# AM335x register map
Vendor: Texas Instruments; Series: Sitara AM335x; File version: 1.1
CPU: Cortex-A8 r0p0, little endian
Registers are 32-bit, read-write, reset 0x0 unless marked. A register's access mark holds for its fields unless they carry their own. Offsets are from the block's base; [hi:lo] are bit positions.

## UART — UART0 module
Base 0x44E09000
0x00 THR
  [7:0] THR wo — Transmit holding register.[Value 0 to FFh.]
0x00 RHR
  [7:0] RHR ro — Receive holding register..[Value 0 to FFh.]
0x00 DLL
  [7:0] CLOCK_LSB — Divisor latches low.Stores the 8 LSB divisor value.[Value 0 to FFh.]
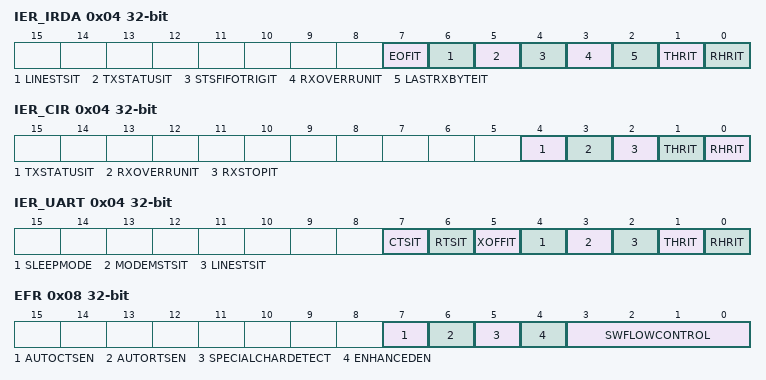
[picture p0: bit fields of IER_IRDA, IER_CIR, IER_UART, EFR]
0x04 IER_IRDA
  [7] EOFIT — bit: 7 (RW) received EOF interrupt [0x0 = disable; 0x1 = enable ]
  [6] LINESTSIT — bit: 6 (RW) receiver line status interrupt [0x0 = disable; 0x1 = enable ]
  [5] TXSTATUSIT — bit: 5 (RW) TX status interrupt [0x0 = disable; 0x1 = enable ]
  [4] STSFIFOTRIGIT — bit: 4 (RW) status FIFO trigger level interrupt [0x0 = disable; 0x1 = enable ]
  [3] RXOVERRUNIT — bit: 3 (RW) RX overrun interrupt [0x0 = disable; 0x1 = enable ]
  [2] LASTRXBYTEIT — bit: 2 (RW) last byte of frame in RX FIFO interrupt [0x0 = disable; 0x1 = enable ]
  [1] THRIT — bit: 1 (RW) THR interrupt [0x0 = disable; 0x1 = enable ]
  [0] RHRIT — bit: 0 (RW) RHR interrupt [0x0 = disable; 0x1 = enable ]
0x04 IER_CIR
  [4] TXSTATUSIT — bit: 5 (RW) TX status interrupt [0x0 = disable; 0x1 = enable ]
  [3] RXOVERRUNIT — bit: 3 (RW) RX overrun interrupt [0x0 = disable; 0x1 = enable ]
  [2] RXSTOPIT — bit: 2 (RW) RX stop interrupt [0x0 = disable; 0x1 = enable ]
  [1] THRIT — bit: 1 (RW) THR interrupt [0x0 = disable; 0x1 = enable ]
  [0] RHRIT — bit: 0 (RW) RHR interrupt [0x0 = disable; 0x1 = enable ]
0x04 IER_UART
  [7] CTSIT — bit: 7 (RW) Can be written only when EFR.ENHANCEDEN = 1. CTS (active-low) interrupt [0x0 = disable; 0x1 = enable ]
  [6] RTSIT — bit: 6 (RW) Can be written only when EFR.ENHANCEDEN = 1. RTS (active-low) interrupt [0x0 = disable; 0x1 = enable ]
  [5] XOFFIT — bit: 5 (RW) Can be written only when EFR.ENHANCEDEN = 1. XOFF interrupt [0x0 = disable; 0x1 = enable ]
  [4] SLEEPMODE — bit: 4 (RW) Can be only written when EFR.ENHANCEDEN = 1. Sleep mode
  [3] MODEMSTSIT — bit: 3 (RW) modem status register interrupt [0x0 = disable; 0x1 = enable ]
  [2] LINESTSIT — bit: 2 (RW) receiver line status interrupt [0x0 = disable; 0x1 = enable ]
  [1] THRIT — bit: 1 (RW) THR interrupt [0x0 = disable; 0x1 = enable ]
  [0] RHRIT — bit: 0 (RW) RHR interrupt and time out interrupt [0x0 = disable; 0x1 = enable ]
0x04 DLH
  [5:0] CLOCK_MSB — Divisor latches high. Stores the 6 MSB divisor value.[Value 0x0 to 0x3F.]
0x08 EFR
  [7] AUTOCTSEN — bit: 7 (RW) Auto-CTS enable bit (UART mode only). [0x0 = Normal operation.; 0x1 = Auto-CTS flow control is enabled; transmission is halted when
  [6] AUTORTSEN — bit: 6 (RW) Auto-RTS enable bit (UART mode only). [0x0 = Normal operation.; 0x1 = Auto-RTS flow control is enabled; RTS (active-low) pin goes
  [5] SPECIALCHARDETECT — bit: 5 (RW) Special character detect (UART mode only).[0x0 = Normal operation.; 0x1 = Special character
  [4] ENHANCEDEN — bit: 4 (RW) Enhanced functions write enable bit.Writing to IER[7:4], FCR[5:4], and MCR[7:5].[see e_ENH]
  [3:0] SWFLOWCONTROL — Combinations of software flow control can be selected by programming this bit. [ see e_SW_TX_FLOW_CTRL and e_SW_RX_FLOW_CTRL]
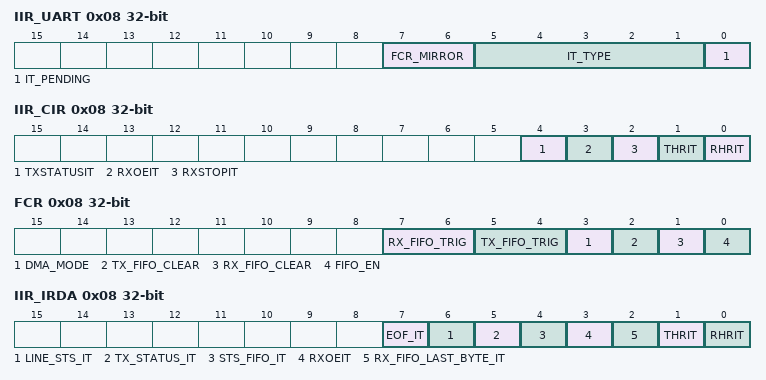
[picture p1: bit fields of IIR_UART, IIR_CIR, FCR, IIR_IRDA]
0x08 IIR_UART
  [7:6] FCR_MIRROR — Mirror the contents of FCR[0] on both bits.
  [5:1] IT_TYPE — Seven possible interrupts in UART mode. Other combinations never occur: [see e_IT_TYPES]
  [0] IT_PENDING — bit: 0 (RW) Interrupt pending. [0x0 = An interrupt is pending.; 0x1 = No interrupt is pending.]
0x08 IIR_CIR
  [4] TXSTATUSIT — bit: 5 (RW) TX status interrupt [0x0 = inactive; 0x1 = active ]
  [3] RXOEIT — bit: 3 (RW) RX overrun interrupt [0x0 = inactive; 0x1 = active ]
  [2] RXSTOPIT — bit: 2 (RW) Receive stop interrupt [0x0 = inactive; 0x1 = active ]
  [1] THRIT — bit: 1 (RW) THR interrupt [0x0 = inactive; 0x1 = active ]
  [0] RHRIT — bit: 0 (RW) RHR interrupt [0x0 = inactive; 0x1 = active ]
0x08 FCR
  [7:6] RX_FIFO_TRIG — bit: 6,7 (RW) Sets the trigger level for the RX FIFO: If SCR[7] = 0 and TLR[7] to
  [5:4] TX_FIFO_TRIG — bit: 4,5 (W) Can be written only if EFR.ENHANCEDEN = 1. Sets the trigger level for the TX FIFO: If SCR[6] = 0 and TLR[3] to
  [3] DMA_MODE — bit: 3 (W) Can be changed only when the baud clock is not running (DLL and DLH cleared to 0).
  [2] TX_FIFO_CLEAR — bit: 2 (W) [ 0x0 = No change.;
  [1] RX_FIFO_CLEAR — bit: 1 (W) [ 0x0 = No change.;
  [0] FIFO_EN — bit: 0 (W) Can be changed only when the baud clock is not running (DLL and DLH cleared to 0). [0x0 = Disables rcv FIFO; 0x1 = Enables rcv FIFO ]
0x08 IIR_IRDA
  [7] EOF_IT — bit: 7 (R) Received EOF [0x0 = inactive; 0x1 = active ]
  [6] LINE_STS_IT — bit: 6 (R) Receiver line status interrupt [0x0 = inactive; 0x1 = active ]
  [5] TX_STATUS_IT — bit: 5 (R) TX status interrupt [0x0 = inactive; 0x1 = active ]
  [4] STS_FIFO_IT — bit: 4 (R) Status FIFO trigger level interrupt [0x0 = inactive; 0x1 = active ]
  [3] RXOEIT — bit: 3 (R) RX overrun interrupt [0x0 = inactive; 0x1 = active ]
  [2] RX_FIFO_LAST_BYTE_IT — bit: 2 (R) Last byte of frame in RX FIFO interrupt [0x0 = inactive; 0x1 = active ]
  [1] THRIT — bit: 1 (R) THR interrupt [0x0 = inactive; 0x1 = active ]
  [0] RHRIT — bit: 0 (R) RHR interrupt [0x0 = inactive; 0x1 = active ]
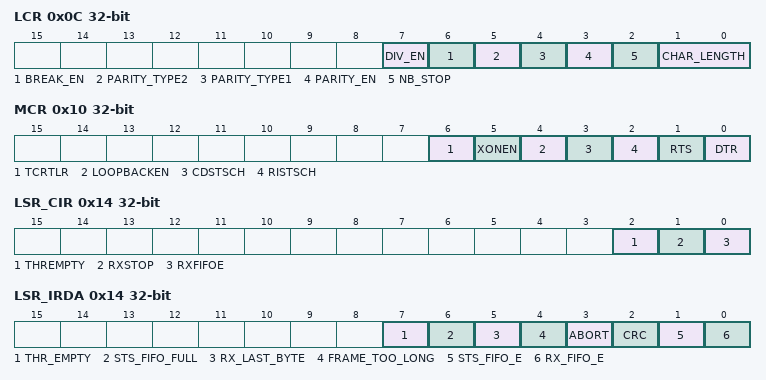
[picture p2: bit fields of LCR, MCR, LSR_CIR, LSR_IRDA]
0x0C LCR
  [7] DIV_EN — bit: 7 (RW) Divisor latch enable. [0x0 = Normal operating condition.;
  [6] BREAK_EN — bit: 6 (RW) Break control bit. Note: When LCR[6] is set to 1, the TX line is forced to 0 and remains
  [5] PARITY_TYPE2 — bit: 5 (RW) If LCR[3] = 1, then: [0x0 = If LCR[5] = 0, LCR[4] selects the forced parity format.;
  [4] PARITY_TYPE1 — bit: 4 (RW) If LCR[3] = 1, then: [0x0 = Odd parity is generated.; 0x1 = Even parity is generated. ]
  [3] PARITY_EN — bit: 3 (RW) Parity bit. [0x0 = No parity;
  [2] NB_STOP — bit: 2 (RW) Specifies the number of stop bits. [0x0 = 1 stop bit (word length = 5, 6, 7, 8).;
  [1:0] CHAR_LENGTH — bit: 0,1 (RW) Specifies the word length to be transmitted or received. [ see e_CHAR_LENGHT ]
0x10 MCR
  [6] TCRTLR — bit: 6 (RW) Can be written only when EFR.ENHANCEDEN = 1. [0x0 = No action.; 0x1 = Enables access to the TCR and TLR registers. ]
  [5] XONEN — bit: 5 (RW) Can be written only when EFR.ENHANCEDEN = 1. [0x0 = Disable XON any function.; 0x1 = Enable XON any function. ]
  [4] LOOPBACKEN — bit: 4 (RW) Loopback mode enable. [0x0 = Normal operating mode.; 0x1 = Enable local loopback mode (internal). In this mode, the
  [3] CDSTSCH — bit: 3 (RW) CDSTSCH. [0x0 = In loopback mode, forces DCD (active-low) input high and IRQ outputs to INACTIVE state.;
  [2] RISTSCH — bit: 2 (RW) RISTSCH. [ 0x0 = In loopback mode, forces RI (active-low) input inactive (high).;
  [1] RTS — bit: 1 (RW) In loopback mode, controls MSR[4]. If auto-RTS is enabled, the RTS (active-low) output is controlled by
  [0] DTR — bit: 0 (RW) DTR. [0x0 = Force DTR (active-low) output (used in loopback mode) to inactive (high).;
0x10 XON1_ADDR1
  [7:0] XONWORD1 — Stores the 8 bit XON1 character in UART modes and ADDR1 address 1 in IrDA modes.
0x14 XON2_ADDR2
  [7:0] XONWORD2 — Stores the 8 bit XON2 character in UART modes and ADDR2 address 2 in IrDA modes.
0x14 LSR_CIR
  [2] THREMPTY — bit: 4 (R) THREMPTY. [ 0x0 = Transmit holding register (TX FIFO) is not empty.;
  [1] RXSTOP — bit: 2 (R) The RXSTOP is generated based on the value set in the BOF
  [0] RXFIFOE — bit: 0 (R) RXFIFOE. [0x0 = At least one data character in the RX FIFO.;
0x14 LSR_IRDA
  [7] THR_EMPTY — bit: 7 (R) [0x0 = Transmit holding register (TX FIFO) is not empty;
  [6] STS_FIFO_FULL — bit: 6 (R) [0x0 = Status FIFO is not full.; 0x1 = Status FIFO is full. ]
  [5] RX_LAST_BYTE — bit: 5 (R) [0x0 = The RX FIFO (RHR) does not contain the last byte of the frame to be read.;
  [4] FRAME_TOO_LONG — bit: 4 (R) [0x0 = No frame-too-long error in frame.; 0x1 = Frame-too-long error in the frame at the top of the status FIFO
  [3] ABORT — bit: 3 (R) [0x0 = No abort pattern error in frame.; 0x1 = Abort pattern received. SIR and MIabort pattern. FIR: Illegal symbol. ]
  [2] CRC — bit: 2 (R) [0x0 = No CRC error in frame.; 0x1 = CRC error in the frame at the top of the status FIFO (next character to be read). ]
  [1] STS_FIFO_E — bit: 1 (R) [0x0 = Status FIFO is not empty.; 0x1 = Status FIFO is empty. ]
  [0] RX_FIFO_E — bit: 0 (R) [0x0 = At least one data character in the RX FIFO.; 0x1 = No data in the receive FIFO. ]
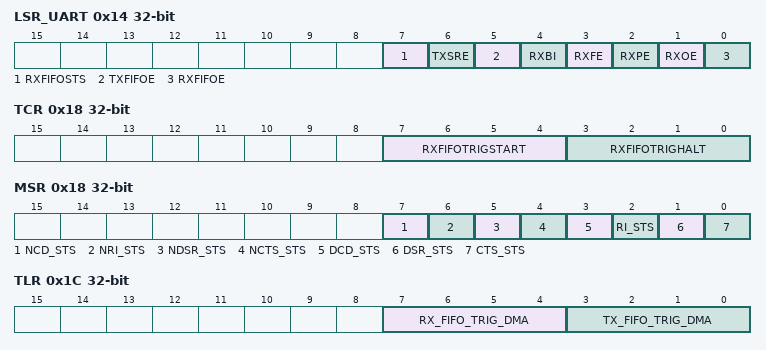
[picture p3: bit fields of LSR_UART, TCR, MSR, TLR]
0x14 LSR_UART
  [7] RXFIFOSTS — bit: 7 (R) [0x0 = Normal operation.;
  [6] TXSRE — bit: 6 (R) [0x0 = Transmitter hold (TX FIFO) and shift registers are not empty.;
  [5] TXFIFOE — bit: 5 (R) [0x0 = Transmit hold register (TX FIFO) is not empty.;
  [4] RXBI — bit: 4 (R) [0x0 = No break condition.; 0x1 = A break was detected while the data being read from the RX
  [3] RXFE — bit: 3 (R) [0x0 = No framing error in data being read from RX FIFO.;
  [2] RXPE — bit: 2 (R) [0x0 = No parity error in data being read from RX FIFO.; 0x1 = Parity error in data being read from RX FIFO. ]
  [1] RXOE — bit: 1 (R) [0x0 = No overrun error.; 0x1 = Overrun error occurred. Set when the character held in the
  [0] RXFIFOE — bit: 0 (R) [0x0 = No data in the receive FIFO.; 0x1 = At least one data character in the RX FIFO. ]
0x18 TCR
  [7:4] RXFIFOTRIGSTART — RX FIFO trigger level to RESTORE transmission (0 to 60).
  [3:0] RXFIFOTRIGHALT — RX FIFO trigger level to HALT transmission (0 to 60).
0x18 MSR
  [7] NCD_STS — bit: 7 (R) This bit is the complement of the DCD (active-low) input.
  [6] NRI_STS — bit: 6 (R) This bit is the complement of the RI (active-low) input.
  [5] NDSR_STS — bit: 5 (R) This bit is the complement of the DSR (active-low) input.
  [4] NCTS_STS — bit: 4 (R) This bit is the complement of the CTS (active-low) input.
  [3] DCD_STS — bit: 3 (R) DCD_STS.[0x0 = No change.; 0x1 = Indicates that DCD (active-low) input (or MCR[3] in loopback
  [2] RI_STS — bit: 2 (R) RI_STS. [0x0 = No change.; 0x1 = Indicates that RI (active-low) input (or MCR[2] in loopback
  [1] DSR_STS — bit: 1 (R) DSR_STS.[0x0 = No change.; 0x1 = Indicates that DSR (active-low) input (or MCR[0] in loopback
  [0] CTS_STS — bit: 0 (R) CTS_STS.[0x0 = No change.; 0x1 = Indicates that CTS (active-low) input (or MCR[1] in loopback
0x18 XOFF1
  [7:0] XOFFWORD1 — Stores the 8 bit XOFF1 character in UART modes.
0x1C SPR
  [7:0] SPR_WORD — Scratchpad register.
0x1C TLR
  [7:4] RX_FIFO_TRIG_DMA — Receive FIFO trigger level.
  [3:0] TX_FIFO_TRIG_DMA — Transmit FIFO trigger level.
0x1C XOFF2
  [7:0] XOFFWORD2 — Stores the 8 bit XOFF2 character in UART modes.
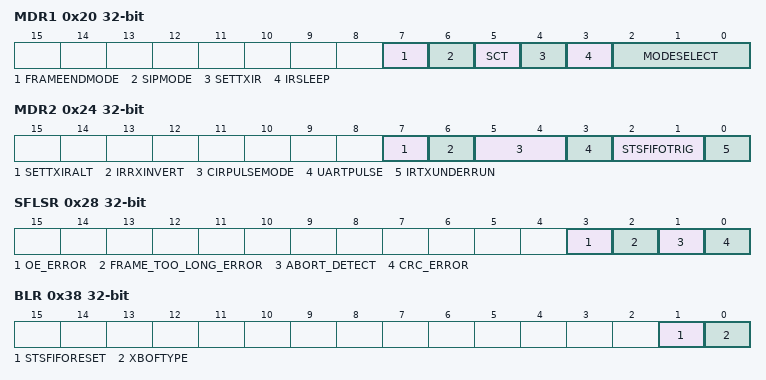
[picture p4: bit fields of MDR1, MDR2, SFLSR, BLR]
0x20 MDR1
  [7] FRAMEENDMODE — bit: 7 (RW) IrDA mode only. [0x0 = Frame-length method.; 0x1 = Set EOT bit method. ]
  [6] SIPMODE — bit: 6 (RW) MIR/FIR modes only. [0x0 = Manual SIP mode: SIP is generated with the control of ACREG[3].;
  [5] SCT — bit: 5 (RW) Store and control the transmission. [0x0 = Starts the infrared transmission when a value is written to the THR register.;
  [4] SETTXIR — bit: 4 (RW) Used to configure the infrared transceiver. [0x0 = If MDR2[7] = 0, no action; if MDR2[7] = 1, TXIR pin output is forced low.;
  [3] IRSLEEP — bit: 3 (RW) IrDA/CIR sleep mode. [0x0 = disabled; 0x1 = enabled ]
  [2:0] MODESELECT — UART/IrDA/CIR mode selection. [ see e_MODESELECT ]
0x24 MDR2
  [7] SETTXIRALT — bit: 7 (RW) Provides alternate functionality for MDR1[4]. [0x0 = Normal mode; 0x1 = Alternate mode for SETTXIR ]
  [6] IRRXINVERT — bit: 6 (RW) Only for IR mode (IrDA and CIR).
  [5:4] CIRPULSEMODE — bit: 4,5 (RW) CIR pulse modulation definition. Defines high level of the pulse width associated with a digit:[ see e_CIRPULSE_MODULATION ]
  [3] UARTPULSE — bit: 3 (RW) UART mode only.Used to allow pulse shaping in UART mode.[0x0 = Normal UART mode.; 0x1 = UART mode with pulse shaping. ]
  [2:1] STSFIFOTRIG — bit: 1,2 (RW) Only for IrDA mode.Frame status FIFO threshold select: [see e_IRDA_FIFO_TIRGLVL ]
  [0] IRTXUNDERRUN — bit: 0 (R) IrDA transmission status interrupt. [0x0 = frame was transmitted successfully without error.;
0x28 TXFLL
  [7:0] TXFLL wo — LSB register used to specify the frame length.
0x28 SFLSR
  [3] OE_ERROR — bit: 4 (R) [0x0 = No error; 0x1 = Overrun error in RX FIFO when frame at top of RX FIFO was received. ]
  [2] FRAME_TOO_LONG_ERROR — bit: 3 (R) [0x0 = No error; 0x1 = Frame-length too long error in frame at top of RX FIFO. ]
  [1] ABORT_DETECT — bit: 2 (R) [0x0 = No error; 0x1 = Abort pattern detected in frame at top of RX FIFO. ]
  [0] CRC_ERROR — bit: 1 (R) [0x0 = No error; 0x1 = CRC error in frame at top of RX FIFO. ]
0x2C RESUME
  [7:0] RESUME ro — Dummy read to restart the TX or RX, value 0 to FFh.
0x2C TXFLH
  [4:0] TXFLH wo — MSB register used to specify the frame length, value 0 to 1Fh.
0x30 RXFLL
  [7:0] RXFLL wo — LSB register used to specify the frame length in reception, value 0 to FFh.
0x30 SFREGL
  [7:0] SFREGL ro — LSB register used to specify the frame length in reception, value 0 to FFh.
0x34 SFREGH
  [3:0] SFREGH ro — MSB part of the frame length, value 0 to Fh.
0x34 RXFLH
  [3:0] RXFLH wo — MSB register used to specify the frame length in reception, value 0 to Fh.
0x38 BLR
  [1] STSFIFORESET — bit: 7 (RW) Status FIFO reset.This bit is self-clearing.
  [0] XBOFTYPE — bit: 6 (RW) SIR xBOF select.[0x0 = FFh start pattern is used.; 0x1 = C0h start pattern is used. ]
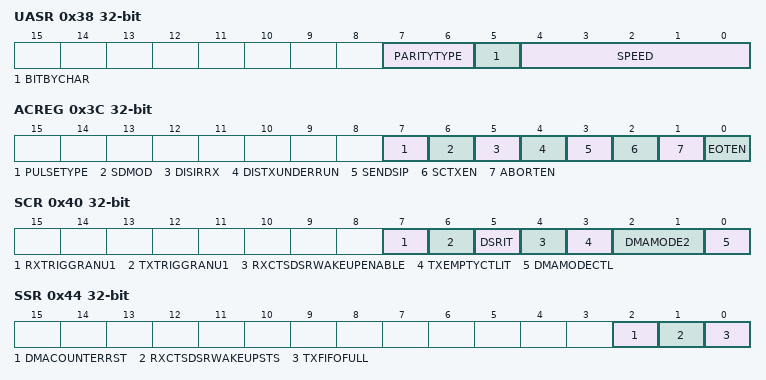
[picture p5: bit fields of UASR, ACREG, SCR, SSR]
0x38 UASR
  [7:6] PARITYTYPE — bit: 6,7 (R) Type of the parity in UART autobauding mode. [ see e_PARITY_TYPE ]
  [5] BITBYCHAR — bit: 5 (R) Number of bits by characters. [ 0x0 = 7-bit character identified.;
  [4:0] SPEED ro — Speed. [ see e_AUTOBAUD_SPEED ]
0x3C ACREG
  [7] PULSETYPE — bit: 7 (RW) SIR pulse-width select: [0x0 = 3/16 of baud-rate pulse width; 0x1 = 1.6 microseconds ]
  [6] SDMOD — bit: 6 (RW) Primary output used to configure transceivers.Connected to the SD/MODE input pin of IrDA transceivers.[0x0 = SD pin is set to high.;
  [5] DISIRRX — bit: 5 (RW) Disable RX input. [0x0 = Normal operation (RX input automatically disabled during
  [4] DISTXUNDERRUN — bit: 4 (RW) Disable TX underrun. [ 0x0 = Long stop bits cannot be transmitted. TX underrun is enabled.;
  [3] SENDSIP — bit: 3 (RW) MIR/FIR modes only. Send serial infrared interaction pulse (SIP).
  [2] SCTXEN — bit: 2 (RW) Store and control TX start. When MDR1[5] = 1 and the LH writes 1 to this bit, the TX statemachine
  [1] ABORTEN — bit: 1 (RW) Frame abort. The LH can intentionally abort transmission of a frame by writing 1 to
  [0] EOTEN — bit: 0 (RW) EOT (end-of-transmission) bit. The LH writes 1 to this bit just before it writes the last byte to the TX
0x40 SCR
  [7] RXTRIGGRANU1 — bit: 7 (RW) [0x0 = Disables the granularity of 1 for trigger RX level.; 0x1 = Enables the granularity of 1 for trigger RX level. ]
  [6] TXTRIGGRANU1 — bit: 6 (RW) [0x0 = Disables the granularity of 1 for trigger TX level.; 0x1 = Enables the granularity of 1 for trigger TX level. ]
  [5] DSRIT — bit: 5 (RW) [0x0 = Disables DSR (active-low) interrupt.; 0x1 = Enables DSR (active-low) interrupt. ]
  [4] RXCTSDSRWAKEUPENABLE — bit: 4 (RW) [0x0 = Disables the WAKE UP interrupt and clears SSR[1].;
  [3] TXEMPTYCTLIT — bit: 3 (RW) [0x0 = Normal mode for THR interrupt.; 0x1 = THR interrupt is generated when TX FIFO and TX shift register are empty. ]
  [2:1] DMAMODE2 — bit: 1,2 (RW) Specifies the DMA mode valid if SCR[0] = 1, then:[ see e_SCR_DMA_MODE ]
  [0] DMAMODECTL — bit: 0 (RW) [0x0 = The DMAMODE is set with FCR[3].; 0x1 = The DMAMODE is set with SCR[2:1]. ]
0x44 SSR
  [2] DMACOUNTERRST — bit: 2 (RW) [ 0x0 = The DMA counter will not be reset, if the corresponding FIFO is reset (via FCR[1] or FCR[2]).;
  [1] RXCTSDSRWAKEUPSTS — bit: 1 (R) Pin falling edge detection: Reset only when SCR[4] is reset to 0. [0x0 = No falling-edge event on RX, CTS (active-low), and DSR
  [0] TXFIFOFULL — bit: 0 (R) [ 0x0 = TX FIFO is not full.; 0x1 = TX FIFO is full. ]
0x48 EBLR
  [7:0] EBLR — IrDA mode: This register allows definition of up to 176 xBOFs, the
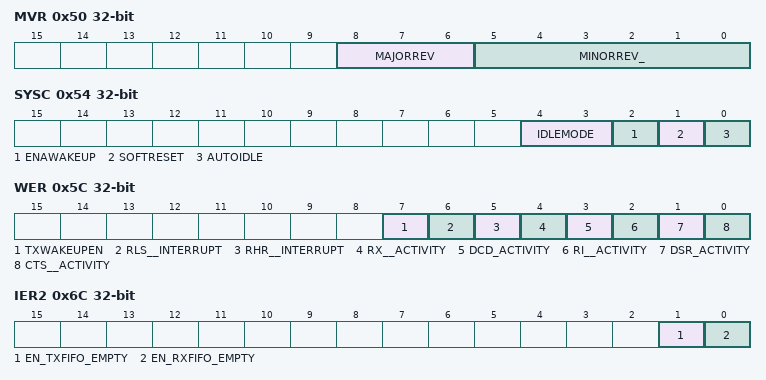
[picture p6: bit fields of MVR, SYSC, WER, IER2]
0x50 MVR
  [8:6] MAJORREV ro — Major revision number of the module.
  [5:0] MINORREV_ ro — Minor revision number of the module.
0x54 SYSC
  [4:3] IDLEMODE — bit: 3,4 (RW) Power management req/ack control. [ see e_IDLEMODE]
  [2] ENAWAKEUP — bit: 2 (RW) Wakeup control. [0x0 = Wakeup is disabled.; 0x1 = Wakeup capability is enabled. ]
  [1] SOFTRESET — bit: 1 (RW) Software reset. Set this bit to 1 to trigger a module reset.
  [0] AUTOIDLE ro — bit: 0 (RW) Internal interface clock-gating strategy. [0x0 = Clock is running.; 0x1 = Reserved. ]
0x58 SYSS
  [0] RESETDONE — bit: 0 (RW) Internal reset monitoring. [0x0 = Internal module reset is ongoing.; 0x1 = Reset complete. ]
0x5C WER
  [7] TXWAKEUPEN — bit: 7 (RW) Wake-up interrupt. [0x0 = Event is not allowed to wake up the system.;
  [6] RLS__INTERRUPT — bit: 6 (RW) Receiver line status interrupt. [0x0 = Event is not allowed to wake up the system.;
  [5] RHR__INTERRUPT — bit: 5 (RW) [0x0 = Event is not allowed to wake up the system.;
  [4] RX__ACTIVITY — bit: 4 (RW) [0x0 = Event is not allowed to wake up the system.;
  [3] DCD_ACTIVITY — bit: 3 (RW) [0x0 = Event is not allowed to wake up the system.;
  [2] RI__ACTIVITY — bit: 2 (RW) [0x0 = Event is not allowed to wake up the system.;
  [1] DSR_ACTIVITY — bit: 1 (RW) [0x0 = Event is not allowed to wake up the system.;
  [0] CTS__ACTIVITY — bit: 0 (RW) [0x0 = Event is not allowed to wake up the system.;
0x60 CFPS
  [7:0] CFPS — bit: 0 System clock frequency prescaler at (12x multiple).CFPS = 0 is not supported. [ see e_TARGET_CIR_FREQ]
0x64 RXFIFO_LVL
  [7:0] RXFIFO_LVL ro — Level of the RX FIFO.
0x68 TXFIFO_LVL
  [7:0] TXFIFO_LVL ro — Level of the TX FIFO
0x6C IER2
  [1] EN_TXFIFO_EMPTY — bit: 1 (R) [0x0 = Disables EN_TXFIFO_EMPTY interrupt.; 0x1 = Enables EN_TXFIFO_EMPTY interrupt. ]
  [0] EN_RXFIFO_EMPTY — bit: 0 (R) [0x0 = Disables EN_RXFIFO_EMPTY interrupt.; 0x1 = Enables EN_RXFIFO_EMPTY interrupt. ]
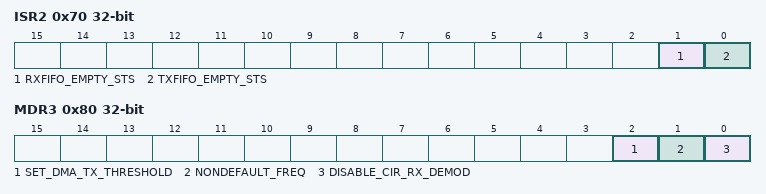
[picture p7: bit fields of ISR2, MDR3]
0x70 ISR2
  [1] RXFIFO_EMPTY_STS — bit: 1 (R) [0x0 = RXFIFO_EMPTY interrupt not pending.; 0x1 = RXFIFO_EMPTY interrupt pending. ]
  [0] TXFIFO_EMPTY_STS — bit: 0 (R) [0x0 = TXFIFO_EMPTY interrupt not pending.; 0x1 = TXFIFO_EMPTY interrupt pending. ]
0x74 FREQ_SEL
  [7:0] FREQ_SEL — Sets the sample per bit if non default frequency is used.
0x80 MDR3
  [2] SET_DMA_TX_THRESHOLD — bit: 2 (RW) [ 0x0 = Disable use of TX DMA Threshold register. Use 64-TX trigger as DMA threshold.;
  [1] NONDEFAULT_FREQ — bit: 1 (RW) [ 0x0 = Disables using NONDEFAULT fclk frequencies.;
  [0] DISABLE_CIR_RX_DEMOD — bit: 0 (RW) [ 0x0 = Enables CIR RX demodulation.;
0x84 TX_DMA_THRESHOLD
  [5:0] TX_DMA_THRESHOLD — Used to manually set the TX DMA threshold level.
